VERSION ""

NS_ :

BS_:

BU_: front_ecu central_ecu rear_ecu rr_ecu rl_ecu fr_ecu fl_ecu dash

BO_ 512 rear_daq: 114 Vector__XXX
 SG_ speedometer : 96|6@1+ (0,0) [0|0] "" Vector__XXX
 SG_ tachometer : 112|12@1+ (0,0) [0|0] "" Vector__XXX
 SG_ accel_x : 0|16@1- (0.000244140625,0) [-8|8] "" Vector__XXX
 SG_ accel_y : 16|16@1- (0.000244140625,0) [-8|8] "" Vector__XXX
 SG_ accel_z : 32|16@1- (0.000244140625,0) [-8|8] "" Vector__XXX
 SG_ gyro_x : 48|16@1- (0.061,0) [-1998|1998] "" Vector__XXX
 SG_ gyro_y : 64|16@1- (0.061,0) [-1998|1998] "" Vector__XXX
 SG_ gyro_z : 80|16@1- (0.061,0) [-1998|1998] "" Vector__XXX
 SG_ obj_temp : 128|16@1+ (0.02,-273.15) [-70|380] "" Vector__XXX
 SG_ amb_temp : 144|16@1+ (0.02,-273.15) [-70|380] "" Vector__XXX

BO_ 17 fuck_you: 8 Vector__XXX
 SG_ microstrain : 0|32@1- (0,0) [0|0] "" Vector__XXX

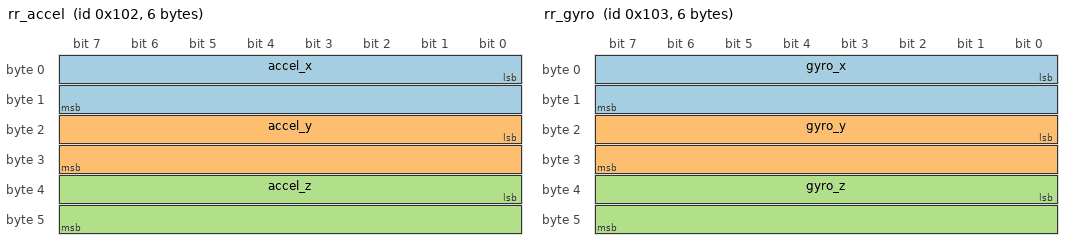
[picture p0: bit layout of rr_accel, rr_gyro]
BO_ 258 rr_accel: 6 rr_ecu
 SG_ accel_x : 0|16@1- (0.000244140625,0) [-8|8] "g" Vector__XXX
 SG_ accel_y : 16|16@1- (0.000244140625,0) [-8|8] "g" Vector__XXX
 SG_ accel_z : 32|16@1- (0.000244140625,0) [-8|8] "g" Vector__XXX

BO_ 259 rr_gyro: 6 rr_ecu
 SG_ gyro_x : 0|16@1- (0.061,0) [-2000|2000] "dps" Vector__XXX
 SG_ gyro_y : 16|16@1- (0.061,0) [-2000|2000] "dps" Vector__XXX
 SG_ gyro_z : 32|16@1- (0.061,0) [-2000|2000] "dps" Vector__XXX

BO_ 260 rr_linpot: 2 rr_ecu
 SG_ travel : 0|16@1+ (0.01,0) [0|655.35] "cm" Vector__XXX

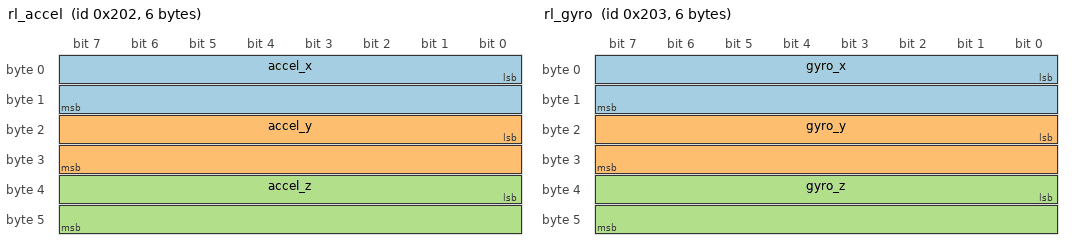
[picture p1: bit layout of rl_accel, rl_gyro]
BO_ 514 rl_accel: 6 rl_ecu
 SG_ accel_x : 0|16@1- (0.000244140625,0) [-8|8] "g" Vector__XXX
 SG_ accel_y : 16|16@1- (0.000244140625,0) [-8|8] "g" Vector__XXX
 SG_ accel_z : 32|16@1- (0.000244140625,0) [-8|8] "g" Vector__XXX

BO_ 515 rl_gyro: 6 rl_ecu
 SG_ gyro_x : 0|16@1- (0.061,0) [-2000|2000] "dps" Vector__XXX
 SG_ gyro_y : 16|16@1- (0.061,0) [-2000|2000] "dps" Vector__XXX
 SG_ gyro_z : 32|16@1- (0.061,0) [-2000|2000] "dps" Vector__XXX

BO_ 516 rl_linpot: 2 rl_ecu
 SG_ travel : 0|16@1+ (0.01,0) [0|655.35] "cm" Vector__XXX

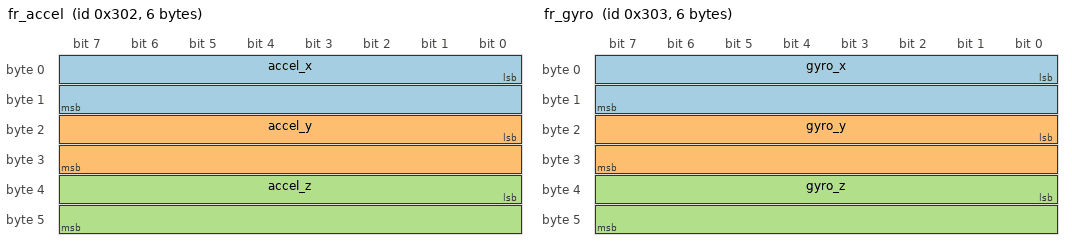
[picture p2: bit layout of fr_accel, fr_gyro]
BO_ 770 fr_accel: 6 fr_ecu
 SG_ accel_x : 0|16@1- (0.000244140625,0) [-8|8] "g" Vector__XXX
 SG_ accel_y : 16|16@1- (0.000244140625,0) [-8|8] "g" Vector__XXX
 SG_ accel_z : 32|16@1- (0.000244140625,0) [-8|8] "g" Vector__XXX

BO_ 771 fr_gyro: 6 fr_ecu
 SG_ gyro_x : 0|16@1- (0.061,0) [-2000|2000] "dps" Vector__XXX
 SG_ gyro_y : 16|16@1- (0.061,0) [-2000|2000] "dps" Vector__XXX
 SG_ gyro_z : 32|16@1- (0.061,0) [-2000|2000] "dps" Vector__XXX

BO_ 772 fr_linpot: 2 fr_ecu
 SG_ travel : 0|16@1+ (0.01,0) [0|655.35] "cm" Vector__XXX

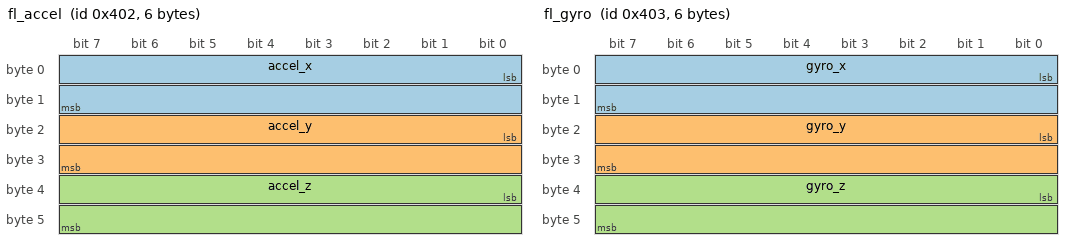
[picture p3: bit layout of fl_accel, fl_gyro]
BO_ 1026 fl_accel: 6 fl_ecu
 SG_ accel_x : 0|16@1- (0.000244140625,0) [-8|8] "g" Vector__XXX
 SG_ accel_y : 16|16@1- (0.000244140625,0) [-8|8] "g" Vector__XXX
 SG_ accel_z : 32|16@1- (0.000244140625,0) [-8|8] "g" Vector__XXX

BO_ 1027 fl_gyro: 6 fl_ecu
 SG_ gyro_x : 0|16@1- (0.061,0) [-2000|2000] "dps" Vector__XXX
 SG_ gyro_y : 16|16@1- (0.061,0) [-2000|2000] "dps" Vector__XXX
 SG_ gyro_z : 32|16@1- (0.061,0) [-2000|2000] "dps" Vector__XXX

BO_ 1028 fl_linpot: 2 fl_ecu
 SG_ travel : 0|16@1+ (0.01,0) [0|655.35] "cm" Vector__XXX

BO_ 1284 speedometer: 2 rear_ecu
 SG_ speed : 0|16@1+ (1,0) [0|65535] "km/h" Vector__XXX

BO_ 1285 tachometer: 2 rear_ecu
 SG_ rpm : 0|16@1+ (1,0) [0|65535] "rpm" Vector__XXX

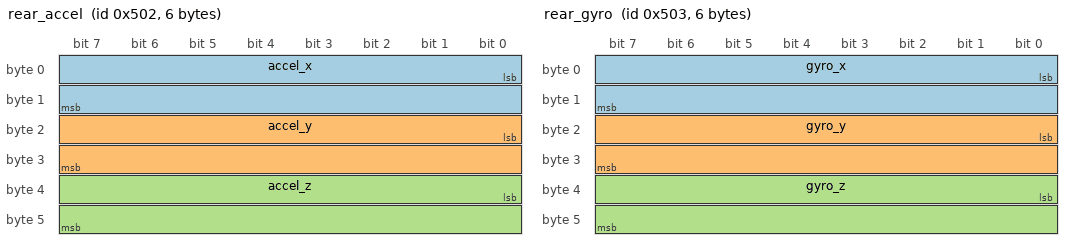
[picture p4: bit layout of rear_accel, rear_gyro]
BO_ 1282 rear_accel: 6 rear_ecu
  SG_ accel_x : 0|16@1- (0.000244140625,0) [-8|8] "g" Vector__XXX
  SG_ accel_y : 16|16@1- (0.000244140625,0) [-8|8] "g" Vector__XXX
  SG_ accel_z : 32|16@1- (0.000244140625,0) [-8|8] "g" Vector__XXX

BO_ 1283 rear_gyro: 6 rear_ecu
  SG_ gyro_x : 0|16@1- (0.061,0) [-2000|2000] "dps" Vector__XXX
  SG_ gyro_y : 16|16@1- (0.061,0) [-2000|2000] "dps" Vector__XXX
  SG_ gyro_z : 32|16@1- (0.061,0) [-2000|2000] "dps" Vector__XXX

BO_ 1538 front_steering: 2 front_ecu
  SG_ steering_angle : 0|16@1- (0.1,0) [-360|360] "deg" Vector__XXX

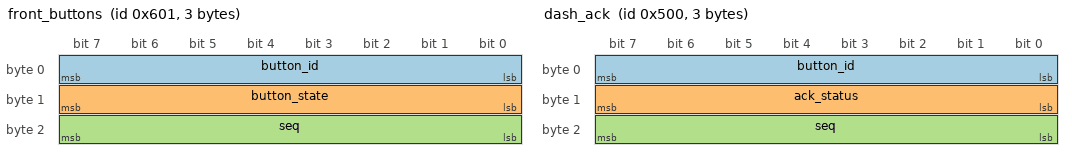
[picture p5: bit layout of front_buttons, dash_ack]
BO_ 1537 front_buttons: 3 front_ecu
 SG_ button_id : 0|8@1+ (1,0) [0|255] "" dash
 SG_ button_state : 8|8@1+ (1,0) [0|255] "" dash
 SG_ seq : 16|8@1+ (1,0) [0|255] "" dash

BO_ 1280 dash_ack: 3 dash
 SG_ button_id : 0|8@1+ (1,0) [0|255] "" front_ecu
 SG_ ack_status : 8|8@1+ (1,0) [0|255] "" front_ecu
 SG_ seq : 16|8@1+ (1,0) [0|255] "" front_ecu

BA_DEF_ BO_  "VFrameFormat" ENUM  "StandardCAN","ExtendedCAN","reserved","J1939PG";
BA_DEF_  "DatabaseVersion" STRING ;
BA_DEF_  "BusType" STRING ;
BA_DEF_  "ProtocolType" STRING ;
BA_DEF_  "DatabaseCompiler" STRING ;
BA_DEF_DEF_  "VFrameFormat" "StandardCAN";
BA_DEF_DEF_  "DatabaseVersion" "";
BA_DEF_DEF_  "BusType" "";
BA_DEF_DEF_  "ProtocolType" "";
BA_DEF_DEF_  "DatabaseCompiler" "";
BA_ "BusType" "CAN";
BA_ "DatabaseCompiler" "UBC BAJA";
BA_ "DatabaseVersion" "1.0.0";

SIG_VALTYPE_ 17 microstrain : 1;
